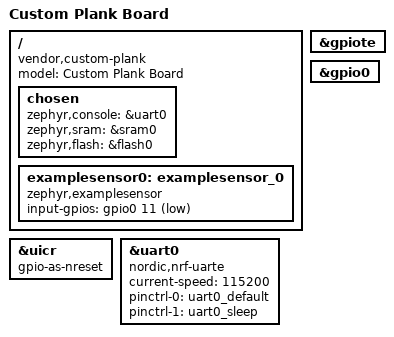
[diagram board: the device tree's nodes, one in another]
/*
 * Copyright (c) 2021 Nordic Semiconductor ASA
 * SPDX-License-Identifier: Apache-2.0
 */

/dts-v1/;
#include <nordic/nrf52840_qiaa.dtsi>
#include "custom_plank-pinctrl.dtsi"

/ {
	model = "Custom Plank Board";
	compatible = "vendor,custom-plank";

	chosen {
		zephyr,console = &uart0;
		zephyr,sram = &sram0;
		zephyr,flash = &flash0;
	};

	examplesensor0: examplesensor_0 {
		compatible = "zephyr,examplesensor";
		input-gpios = <&gpio0 11 (GPIO_PULL_UP | GPIO_ACTIVE_LOW)>;
	};
};

&uicr {
	gpio-as-nreset;
};

&gpiote {
	status = "okay";
};

&gpio0 {
	status = "okay";
};

&uart0 {
	compatible = "nordic,nrf-uarte";
	status = "okay";

	current-speed = <115200>;
	pinctrl-0 = <&uart0_default>;
	pinctrl-1 = <&uart0_sleep>;
	pinctrl-names = "default", "sleep";
};
